# nrf9230_engb_cellrf register map
Vendor: Nordic Semiconductor; Series: nRF92; File version: 1
CPU: CM0 r0p0, little endian, no MPU, no FPU, 2 interrupt priority bits, 33 interrupts
Registers are 32-bit, read-write, reset 0x0 unless marked. A register's access mark holds for its fields unless they carry their own. Offsets are from the block's base; [hi:lo] are bit positions; {n}, {i} and the like mark numbered series; 'fields as' and 'values as' point back to an identical list.

## RXDFEGNSS — HALTI_RX_register_map AhmaRx Digital control register map
Base 0x46034000
0x00 TASKS_RX_START_DIG wo — Starts RX digital filtering.
  [0] TASKS_RX_START_DIG
    1=Trigger task
0x04 TASKS_RX_STOP_DIG wo — Stops RX digital filtering.
  [0] TASKS_RX_STOP_DIG
    1=Trigger task
0x08 TASKS_RX_START_DATA wo — Starts RX data transfer.
  [0] TASKS_RX_START_DATA
    1=Trigger task
0x0C TASKS_RX_STOP_DATA wo — Stops RX data transfer.
  [0] TASKS_RX_STOP_DATA
    1=Trigger task
0x10 TASKS_RX_START_NBPM wo — Starts narrow band power measurement.
  [0] TASKS_RX_START_NBPM
    1=Trigger task
0x18 TASKS_RX_CAPT_SAMPLE_CNT_0 wo — Captures sample counter value to RX_SAMPLE_CNT_CAPT_0 register.
  [0] TASKS_RX_CAPT_SAMPLE_CNT_0
    1=Trigger task
0x1C TASKS_RX_CAPT_SAMPLE_CNT_1 wo — Captures sample counter value to RX_SAMPLE_CNT_CAPT_1 register.
  [0] TASKS_RX_CAPT_SAMPLE_CNT_1
    1=Trigger task
0x20 TASKS_RX_LATCHREADREG wo — Latches set of read-only registers.
  [0] TASKS_RX_LATCHREADREG
    1=Trigger task
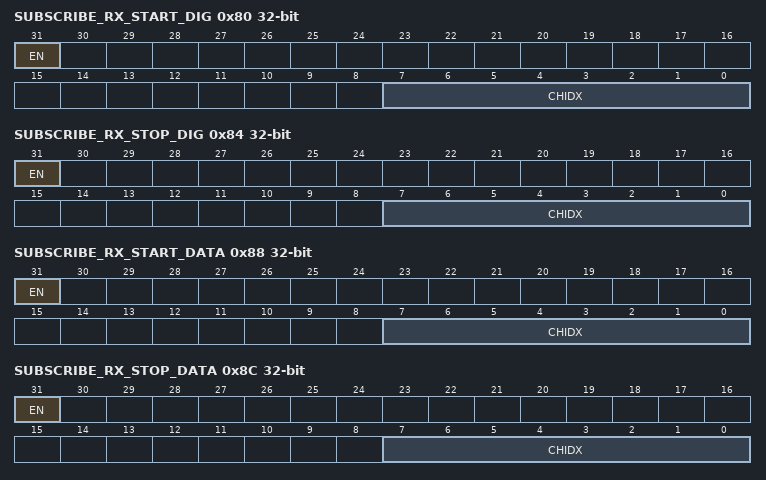
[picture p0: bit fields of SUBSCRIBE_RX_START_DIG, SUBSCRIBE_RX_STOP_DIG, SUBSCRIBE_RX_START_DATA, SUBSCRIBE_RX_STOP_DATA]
0x80 SUBSCRIBE_RX_START_DIG — Subscribe configuration for task RX_START_DIG
  [31] EN
    0=Disabled (Disable subscription); 1=Enabled (Enable subscription)
  [7:0] CHIDX — DPPI channel that task RX_START_DIG will subscribe to
0x84 SUBSCRIBE_RX_STOP_DIG — Subscribe configuration for task RX_STOP_DIG
  [31] EN
    values as SUBSCRIBE_RX_START_DIG.EN
  [7:0] CHIDX — DPPI channel that task RX_STOP_DIG will subscribe to
0x88 SUBSCRIBE_RX_START_DATA — Subscribe configuration for task RX_START_DATA
  [31] EN
    values as SUBSCRIBE_RX_START_DIG.EN
  [7:0] CHIDX — DPPI channel that task RX_START_DATA will subscribe to
0x8C SUBSCRIBE_RX_STOP_DATA — Subscribe configuration for task RX_STOP_DATA
  [31] EN
    values as SUBSCRIBE_RX_START_DIG.EN
  [7:0] CHIDX — DPPI channel that task RX_STOP_DATA will subscribe to
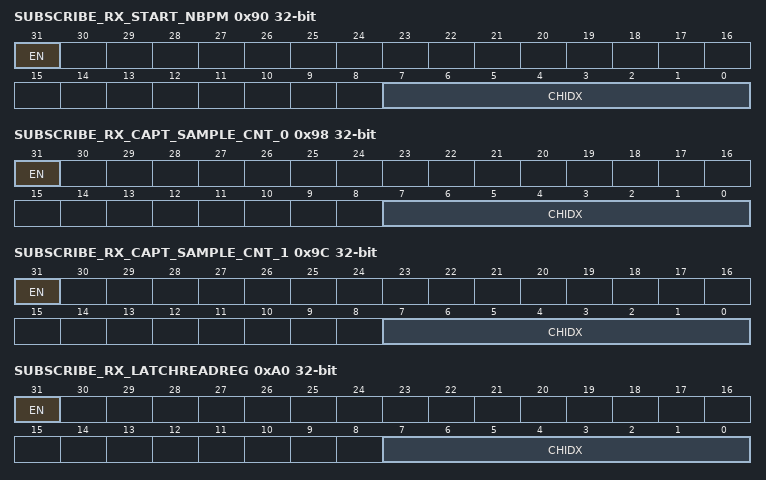
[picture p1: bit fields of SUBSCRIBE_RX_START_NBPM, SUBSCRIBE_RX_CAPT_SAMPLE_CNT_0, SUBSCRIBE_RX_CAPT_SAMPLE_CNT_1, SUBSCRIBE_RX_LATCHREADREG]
0x90 SUBSCRIBE_RX_START_NBPM — Subscribe configuration for task RX_START_NBPM
  [31] EN
    values as SUBSCRIBE_RX_START_DIG.EN
  [7:0] CHIDX — DPPI channel that task RX_START_NBPM will subscribe to
0x98 SUBSCRIBE_RX_CAPT_SAMPLE_CNT_0 — Subscribe configuration for task RX_CAPT_SAMPLE_CNT_0
  [31] EN
    values as SUBSCRIBE_RX_START_DIG.EN
  [7:0] CHIDX — DPPI channel that task RX_CAPT_SAMPLE_CNT_0 will subscribe to
0x9C SUBSCRIBE_RX_CAPT_SAMPLE_CNT_1 — Subscribe configuration for task RX_CAPT_SAMPLE_CNT_1
  [31] EN
    values as SUBSCRIBE_RX_START_DIG.EN
  [7:0] CHIDX — DPPI channel that task RX_CAPT_SAMPLE_CNT_1 will subscribe to
0xA0 SUBSCRIBE_RX_LATCHREADREG — Subscribe configuration for task RX_LATCHREADREG
  [31] EN
    values as SUBSCRIBE_RX_START_DIG.EN
  [7:0] CHIDX — DPPI channel that task RX_LATCHREADREG will subscribe to
0x100 EVENTS_RX_ADC_OVERFLOW — ADC overflow occurred.
  [0] EVENTS_RX_ADC_OVERFLOW
    0=NotGenerated (Event not generated); 1=Generated (Event generated)
0x104 EVENTS_RX_ADC_OVERFLOW_REM — ADC overflow removed.
  [0] EVENTS_RX_ADC_OVERFLOW_REM
    values as EVENTS_RX_ADC_OVERFLOW.EVENTS_RX_ADC_OVERFLOW
0x108 EVENTS_RX_NBPM_READY — Narrow band power measuremnt ready.
  [0] EVENTS_RX_NBPM_READY
    values as EVENTS_RX_ADC_OVERFLOW.EVENTS_RX_ADC_OVERFLOW
0x110 EVENTS_RX_SAMPLE_CNT_COMP_0 — RX sample count matches to value in RX_SAMPLE_CNT_COMP_0 register.
  [0] EVENTS_RX_SAMPLE_CNT_COMP_0
    values as EVENTS_RX_ADC_OVERFLOW.EVENTS_RX_ADC_OVERFLOW
0x114 EVENTS_RX_SAMPLE_CNT_COMP_1 — RX sample count matches to value in RX_SAMPLE_CNT_COMP_1 register.
  [0] EVENTS_RX_SAMPLE_CNT_COMP_1
    values as EVENTS_RX_ADC_OVERFLOW.EVENTS_RX_ADC_OVERFLOW
0x118 EVENTS_RX_SAMPLE_CNT_WRAP — RX sample counter wraps.
  [0] EVENTS_RX_SAMPLE_CNT_WRAP
    values as EVENTS_RX_ADC_OVERFLOW.EVENTS_RX_ADC_OVERFLOW
0x11C EVENTS_RX_DATA_OVERFLOW — RX data overflow occurred.
  [0] EVENTS_RX_DATA_OVERFLOW
    values as EVENTS_RX_ADC_OVERFLOW.EVENTS_RX_ADC_OVERFLOW
0x120 EVENTS_RX_SAMPLE_CNT_CAPT_0 — RX sample count value is captured to RX_SAMPLE_CNT_CAPT_0 register.
  [0] EVENTS_RX_SAMPLE_CNT_CAPT_0
    values as EVENTS_RX_ADC_OVERFLOW.EVENTS_RX_ADC_OVERFLOW
0x124 EVENTS_RX_SAMPLE_CNT_CAPT_1 — RX sample count value is captured to RX_SAMPLE_CNT_CAPT_1 register.
  [0] EVENTS_RX_SAMPLE_CNT_CAPT_1
    values as EVENTS_RX_ADC_OVERFLOW.EVENTS_RX_ADC_OVERFLOW
0x128 EVENTS_RX_READREGLATCHED — Set of read-only registers lacthed.
  [0] EVENTS_RX_READREGLATCHED
    values as EVENTS_RX_ADC_OVERFLOW.EVENTS_RX_ADC_OVERFLOW
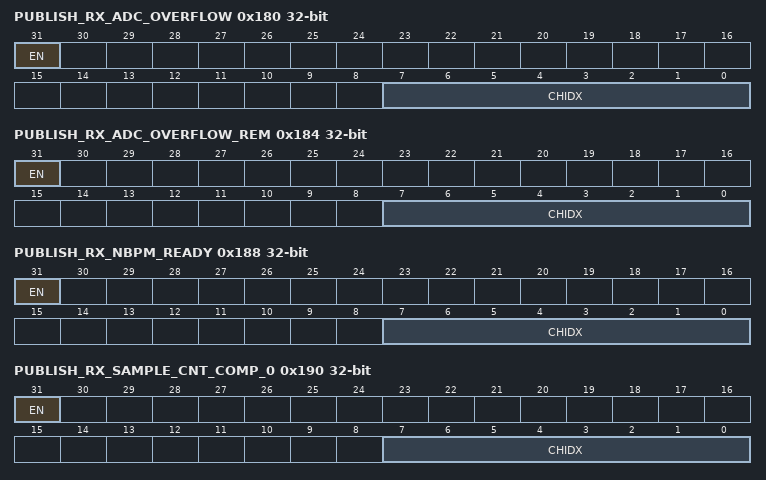
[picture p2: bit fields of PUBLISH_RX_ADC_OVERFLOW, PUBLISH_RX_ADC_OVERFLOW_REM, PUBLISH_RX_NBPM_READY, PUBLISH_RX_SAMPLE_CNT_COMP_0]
0x180 PUBLISH_RX_ADC_OVERFLOW — Publish configuration for event RX_ADC_OVERFLOW
  [31] EN
    0=Disabled (Disable publishing); 1=Enabled (Enable publishing)
  [7:0] CHIDX — DPPI channel that event RX_ADC_OVERFLOW will publish to
0x184 PUBLISH_RX_ADC_OVERFLOW_REM — Publish configuration for event RX_ADC_OVERFLOW_REM
  [31] EN
    values as PUBLISH_RX_ADC_OVERFLOW.EN
  [7:0] CHIDX — DPPI channel that event RX_ADC_OVERFLOW_REM will publish to
0x188 PUBLISH_RX_NBPM_READY — Publish configuration for event RX_NBPM_READY
  [31] EN
    values as PUBLISH_RX_ADC_OVERFLOW.EN
  [7:0] CHIDX — DPPI channel that event RX_NBPM_READY will publish to
0x190 PUBLISH_RX_SAMPLE_CNT_COMP_0 — Publish configuration for event RX_SAMPLE_CNT_COMP_0
  [31] EN
    values as PUBLISH_RX_ADC_OVERFLOW.EN
  [7:0] CHIDX — DPPI channel that event RX_SAMPLE_CNT_COMP_0 will publish to
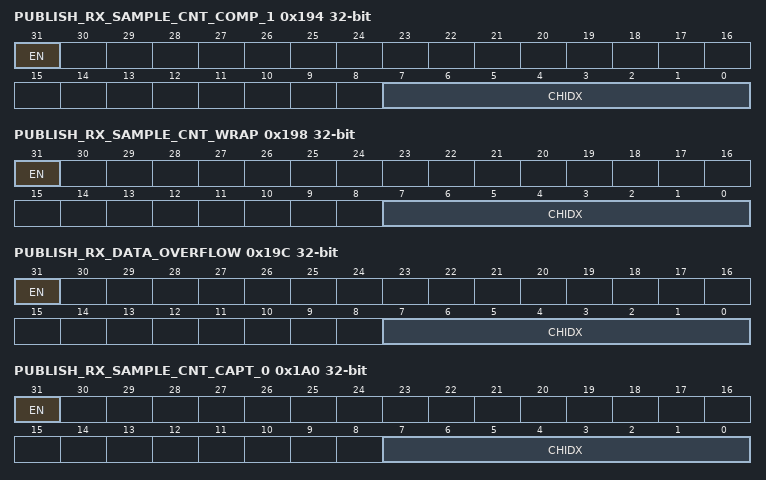
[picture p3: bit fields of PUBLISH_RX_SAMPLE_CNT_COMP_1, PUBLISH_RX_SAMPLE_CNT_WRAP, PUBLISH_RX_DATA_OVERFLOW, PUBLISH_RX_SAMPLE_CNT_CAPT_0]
0x194 PUBLISH_RX_SAMPLE_CNT_COMP_1 — Publish configuration for event RX_SAMPLE_CNT_COMP_1
  [31] EN
    values as PUBLISH_RX_ADC_OVERFLOW.EN
  [7:0] CHIDX — DPPI channel that event RX_SAMPLE_CNT_COMP_1 will publish to
0x198 PUBLISH_RX_SAMPLE_CNT_WRAP — Publish configuration for event RX_SAMPLE_CNT_WRAP
  [31] EN
    values as PUBLISH_RX_ADC_OVERFLOW.EN
  [7:0] CHIDX — DPPI channel that event RX_SAMPLE_CNT_WRAP will publish to
0x19C PUBLISH_RX_DATA_OVERFLOW — Publish configuration for event RX_DATA_OVERFLOW
  [31] EN
    values as PUBLISH_RX_ADC_OVERFLOW.EN
  [7:0] CHIDX — DPPI channel that event RX_DATA_OVERFLOW will publish to
0x1A0 PUBLISH_RX_SAMPLE_CNT_CAPT_0 — Publish configuration for event RX_SAMPLE_CNT_CAPT_0
  [31] EN
    values as PUBLISH_RX_ADC_OVERFLOW.EN
  [7:0] CHIDX — DPPI channel that event RX_SAMPLE_CNT_CAPT_0 will publish to
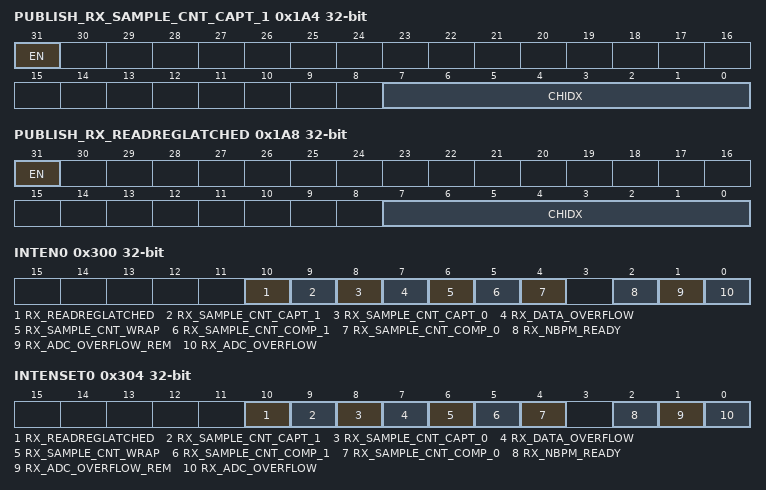
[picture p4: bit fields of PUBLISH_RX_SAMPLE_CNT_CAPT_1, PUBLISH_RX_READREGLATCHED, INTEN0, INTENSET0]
0x1A4 PUBLISH_RX_SAMPLE_CNT_CAPT_1 — Publish configuration for event RX_SAMPLE_CNT_CAPT_1
  [31] EN
    values as PUBLISH_RX_ADC_OVERFLOW.EN
  [7:0] CHIDX — DPPI channel that event RX_SAMPLE_CNT_CAPT_1 will publish to
0x1A8 PUBLISH_RX_READREGLATCHED — Publish configuration for event RX_READREGLATCHED
  [31] EN
    values as PUBLISH_RX_ADC_OVERFLOW.EN
  [7:0] CHIDX — DPPI channel that event RX_READREGLATCHED will publish to
0x300 INTEN0 — Enable or disable interrupt
  [all] fields
    0=Disabled; 1=Enabled
  [10] RX_READREGLATCHED — Enable or disable interrupt for event RX_READREGLATCHED
  [9] RX_SAMPLE_CNT_CAPT_1 — Enable or disable interrupt for event RX_SAMPLE_CNT_CAPT_1
  [8] RX_SAMPLE_CNT_CAPT_0 — Enable or disable interrupt for event RX_SAMPLE_CNT_CAPT_0
  [7] RX_DATA_OVERFLOW — Enable or disable interrupt for event RX_DATA_OVERFLOW
  [6] RX_SAMPLE_CNT_WRAP — Enable or disable interrupt for event RX_SAMPLE_CNT_WRAP
  [5] RX_SAMPLE_CNT_COMP_1 — Enable or disable interrupt for event RX_SAMPLE_CNT_COMP_1
  [4] RX_SAMPLE_CNT_COMP_0 — Enable or disable interrupt for event RX_SAMPLE_CNT_COMP_0
  [2] RX_NBPM_READY — Enable or disable interrupt for event RX_NBPM_READY
  [1] RX_ADC_OVERFLOW_REM — Enable or disable interrupt for event RX_ADC_OVERFLOW_REM
  [0] RX_ADC_OVERFLOW — Enable or disable interrupt for event RX_ADC_OVERFLOW
0x304 INTENSET0 — Enable interrupt
  [all] fields
    on read: 0=Disabled (Read: Disabled); 1=Enabled (Read: Enabled) | on write: 1=Set (Enable)
  [10] RX_READREGLATCHED — Write '1' to enable interrupt for event RX_READREGLATCHED
  [9] RX_SAMPLE_CNT_CAPT_1 — Write '1' to enable interrupt for event RX_SAMPLE_CNT_CAPT_1
  [8] RX_SAMPLE_CNT_CAPT_0 — Write '1' to enable interrupt for event RX_SAMPLE_CNT_CAPT_0
  [7] RX_DATA_OVERFLOW — Write '1' to enable interrupt for event RX_DATA_OVERFLOW
  [6] RX_SAMPLE_CNT_WRAP — Write '1' to enable interrupt for event RX_SAMPLE_CNT_WRAP
  [5] RX_SAMPLE_CNT_COMP_1 — Write '1' to enable interrupt for event RX_SAMPLE_CNT_COMP_1
  [4] RX_SAMPLE_CNT_COMP_0 — Write '1' to enable interrupt for event RX_SAMPLE_CNT_COMP_0
  [2] RX_NBPM_READY — Write '1' to enable interrupt for event RX_NBPM_READY
  [1] RX_ADC_OVERFLOW_REM — Write '1' to enable interrupt for event RX_ADC_OVERFLOW_REM
  [0] RX_ADC_OVERFLOW — Write '1' to enable interrupt for event RX_ADC_OVERFLOW
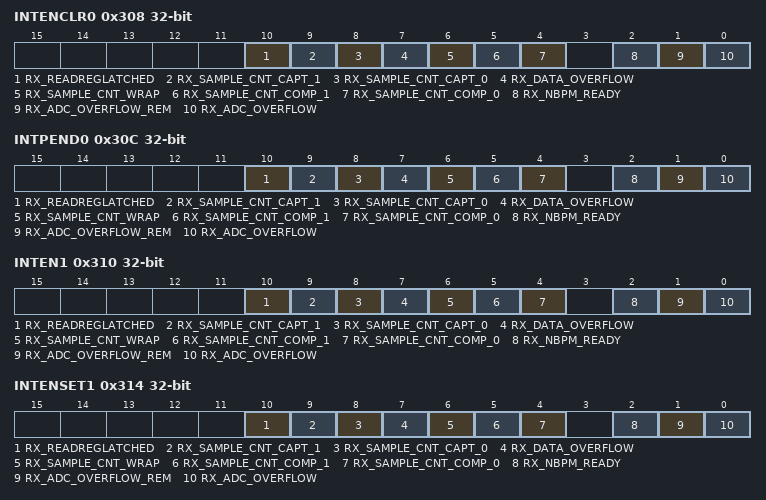
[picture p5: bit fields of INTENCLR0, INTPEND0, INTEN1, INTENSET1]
0x308 INTENCLR0 — Disable interrupt
  [all] fields
    on read: 0=Disabled (Read: Disabled); 1=Enabled (Read: Enabled) | on write: 1=Clear (Disable)
  [10] RX_READREGLATCHED — Write '1' to disable interrupt for event RX_READREGLATCHED
  [9] RX_SAMPLE_CNT_CAPT_1 — Write '1' to disable interrupt for event RX_SAMPLE_CNT_CAPT_1
  [8] RX_SAMPLE_CNT_CAPT_0 — Write '1' to disable interrupt for event RX_SAMPLE_CNT_CAPT_0
  [7] RX_DATA_OVERFLOW — Write '1' to disable interrupt for event RX_DATA_OVERFLOW
  [6] RX_SAMPLE_CNT_WRAP — Write '1' to disable interrupt for event RX_SAMPLE_CNT_WRAP
  [5] RX_SAMPLE_CNT_COMP_1 — Write '1' to disable interrupt for event RX_SAMPLE_CNT_COMP_1
  [4] RX_SAMPLE_CNT_COMP_0 — Write '1' to disable interrupt for event RX_SAMPLE_CNT_COMP_0
  [2] RX_NBPM_READY — Write '1' to disable interrupt for event RX_NBPM_READY
  [1] RX_ADC_OVERFLOW_REM — Write '1' to disable interrupt for event RX_ADC_OVERFLOW_REM
  [0] RX_ADC_OVERFLOW — Write '1' to disable interrupt for event RX_ADC_OVERFLOW
0x30C INTPEND0 ro — Pending interrupts
  [all] fields
    on read: 0=NotPending (Read: Not pending); 1=Pending (Read: Pending)
  [10] RX_READREGLATCHED — Read pending status of interrupt for event RX_READREGLATCHED
  [9] RX_SAMPLE_CNT_CAPT_1 — Read pending status of interrupt for event RX_SAMPLE_CNT_CAPT_1
  [8] RX_SAMPLE_CNT_CAPT_0 — Read pending status of interrupt for event RX_SAMPLE_CNT_CAPT_0
  [7] RX_DATA_OVERFLOW — Read pending status of interrupt for event RX_DATA_OVERFLOW
  [6] RX_SAMPLE_CNT_WRAP — Read pending status of interrupt for event RX_SAMPLE_CNT_WRAP
  [5] RX_SAMPLE_CNT_COMP_1 — Read pending status of interrupt for event RX_SAMPLE_CNT_COMP_1
  [4] RX_SAMPLE_CNT_COMP_0 — Read pending status of interrupt for event RX_SAMPLE_CNT_COMP_0
  [2] RX_NBPM_READY — Read pending status of interrupt for event RX_NBPM_READY
  [1] RX_ADC_OVERFLOW_REM — Read pending status of interrupt for event RX_ADC_OVERFLOW_REM
  [0] RX_ADC_OVERFLOW — Read pending status of interrupt for event RX_ADC_OVERFLOW
0x310 INTEN1 — Enable or disable interrupt
  fields as INTEN0
0x314 INTENSET1 — Enable interrupt
  fields as INTENSET0
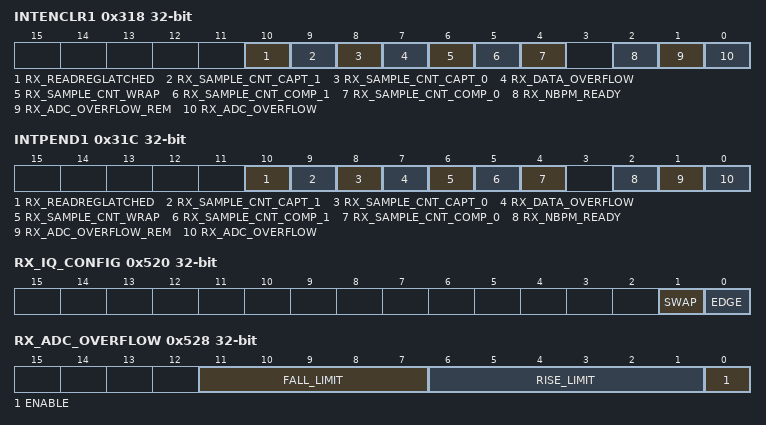
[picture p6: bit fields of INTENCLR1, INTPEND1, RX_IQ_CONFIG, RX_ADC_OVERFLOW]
0x318 INTENCLR1 — Disable interrupt
  fields as INTENCLR0
0x31C INTPEND1 ro — Pending interrupts
  fields as INTPEND0
0x400 RX_STATUS ro
  [0] NBPM_ACTIVE — Narrow band power meter status.
    0=Inactive (NBPM inactive); 1=Active (NBPM active)
0x500 RX_DIG_ENABLE — RX digital enable
  [0] ENABLE — Enable RX digital.
    0=Disabled; 1=Enabled
0x504 RX_DATA_ENABLE
  [0] ENABLE — This bit controls the sync reset signal of the RX data interface.
    0=Disabled; 1=Enabled
0x510 RX_CLK_ENABLE reset 0x1 — RX data enable
  [0] ENABLE — This bit enables the RX data interface clock.
    0=Disabled; 1=Enabled
0x51C RX_CONFIGDONE — RX configuration done.
  [0] ENABLE — This bit indicates that RX digital has been configured. This bit must be asserted at the end of the configuration so that e.g. synchronization of registers to the core works correctly. This bit must be deasserted when RX digital is disabled.
    0=ConfNotDone (Configuration not done); 1=ConfDone (Configuration done)
0x520 RX_IQ_CONFIG — I/Q config
  [1] SWAP — Swaps I and Q paths with each other.
    0=NoSwap; 1=Swapped
  [0] EDGE — Defines on which edge of ADC clock to sample I and Q data.
    0=Falling edge; 1=Rising edge
0x524 RX_ADC_CK_REQ — RX ADC clock request
  [0] REQ — Requests ADC clock.
    0=NoRequest; 1=Request
0x528 RX_ADC_OVERFLOW — RX ADC overflow detection
  [11:7] FALL_LIMIT — Specifies how many ADC clock cycles are elapsed before overflow is removed.
    0=1cycle; 1=2cycles; 31=32cycles
  [6:1] RISE_LIMIT — Specifies how many consecutive cycles with +2 or -2 value must be detected on ADC data input before overflow is detected.
    0=1cycle; 1=2cycles; 63=64cycles
  [0] ENABLE — Enable ADC overflow detection logic.
    0=Disabled; 1=Enabled
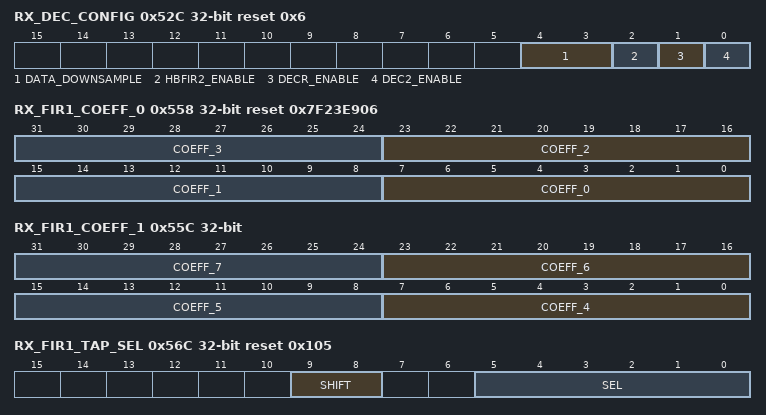
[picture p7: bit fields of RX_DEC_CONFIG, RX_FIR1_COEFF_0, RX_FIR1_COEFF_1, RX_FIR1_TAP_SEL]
0x52C RX_DEC_CONFIG reset 0x6 — RX decimation config
  [4:3] DATA_DOWNSAMPLE — Downsample selection of RX data output.
    0=Disabled; 1=DownsampleBy2; 2=DownsampleBy4; 3=DownsampleBy8
  [2] HBFIR2_ENABLE — Enable half-band FIR with decimation by 2.
    0=Disabled (Disable (i.e. bypass)); 1=Enabled
  [1] DECR_ENABLE — Enable CIC filter with decimation by factor R. R is 5 when normal decimation mode is selected and 4 when alternative decimation mode is selected.
    0=Disabled (Disable (i.e. bypass)); 1=Enabled
  [0] DEC2_ENABLE — Enable CIC filter with decimation by 2.
    0=Disabled (Disable (i.e. bypass)); 1=Enabled
0x530 RX_ALT_DEC_MODE — Alternative decimation mode.
  [0] MODE — Alternative decimation mode selection.
    0=Normal mode; 1=Alternative mode
0x534 RX_DCCOMP_HOLD — DC offset compensation hold
  [0] HOLD — With this bit, the DC estimation LPF can be put into hold mode.
    0=Running; 1=Hold
0x538 RX_DCCOMP_SEL — DC offset compensation selection
  [1:0] SEL — Selection of DC value removal.
    0=Internal (estimated) DC value subtracted from output; 1=External (register) DC value subtracted from output; 2=Bypassed (DC compensation is bypassed.)
0x53C RX_DCCOMP_COEFF_N — Coefficient N value of DC estimation LPF.
  [3:0] COEFF_N — Coefficient N value of DC estimation LPF. This value can be updated while RX digital is active.
0x540 RX_DCCOMP_INIT_I — Initialization value of DC I estimation LPF.
  [16:0] INIT — Initialization value (signed) of DC I estimation LPF. Taken into use when RX digital is activated. This value can be updated while RX digital is active.
0x544 RX_DCCOMP_INIT_Q — Initialization value of DC Q estimation LPF.
  [16:0] INIT — Initialization value (signed) of DC Q estimation LPF. Taken into use when RX digital is activated. This value can be updated while RX digital is active.
0x548 RX_DCCOMP_EXT_I — External value of DC I offset compensation.
  [16:0] EXT — External value (signed) of DC I offset compensation. This value is used when external DC estimation is selected by RX_DCCOMP_SEL register and can be updated while RX digital is active.
0x54C RX_DCCOMP_EXT_Q — External value of DC Q offset compensation.
  [16:0] EXT — External value (signed) of DC Q offset compensation. This value is used when external DC estimation is selected by RX_DCCOMP_SEL register and can be updated while RX digital is active.
0x550 RX_DCCOMP_EST_I ro — Estimated DC I value from DC estimation LPF.
  [16:0] EST — Estimated DC I value (signed) from DC estimation LPF.
0x554 RX_DCCOMP_EST_Q ro — Estimated DC Q value from DC estimation LPF.
  [16:0] EST — Estimated DC Q value (signed) from DC estimation LPF.
0x558 RX_FIR1_COEFF_0 reset 0x7F23E906 — FIR 1 coefficients 0, 1, 2 and 3.
  [8n+7:8n] COEFF_{n} (n=0..3) — FIR 1 coefficient {n} (signed value).
0x55C RX_FIR1_COEFF_1 — FIR 1 coefficients 4, 5, 6 and 7.
  [8n-25:8n-32] COEFF_{n} (n=4..7) — FIR 1 coefficient {n} (signed value).
0x56C RX_FIR1_TAP_SEL reset 0x105 — Number of taps used in FIR 1.
  [9:8] SHIFT — Shift-right the output bits of FIR 1 filter.
    {v}=ShiftBy{v+5} (Shift-right by {v+5}) (v=0..3)
  [5:0] SEL — Number of taps used in FIR 1. The maximum number of taps is 40.
    0=2taps; 1=3taps; 5=7taps; 15=17taps; 25=27taps; 37=39taps
0x588 RX_SCALER_FINE_GAIN — Scaler fine gain.
  [7:0] GAIN — Controls RX digital output fine gain, in ca. 0.034 dB steps. Total gain is sum of SCALER_FINE_GAIN and SCALER_COARSE_GAIN. This value can be updated while RX digital is active.
    0=0p000dB (+0.000 dB); 1=0p034dB (+0.034 dB); 2=0p068dB (+0.068 dB); 255=6p004dB (+6.004 dB)
0x58C RX_SCALER_COARSE_GAIN — Scaler coarse gain.
  [4:0] GAIN — Controls RX digital output coarse gain, in 6.02 dB steps. Total gain is sum of SCALER_FINE_GAIN and SCALER_COARSE_GAIN. This value can be updated while RX digital is active.
    0=m90p31dB (-90.31 dB); 1=m84p29dB (-84.29 dB); 14=m6p02dB (-6.02 dB); 15=0p00dB (+0.00 dB); 16=6p02dB (+6.02 dB); 30=90p31dB (+90.31 dB); 31=96p33dB (+96.33 dB)
0x590 RX_NBPM_DATA_SEL reset 0x1 — Narrow band power meter input data selection.
  [0] SEL — Selects input data of narrow band power meter.
    0=DecAndFilt (Decimation and filtering block output.); 1=Scaler output
0x594 RX_NBPM_FACTOR_L — Narrow band power meter input data selection.
  [2:0] FACTOR — Specifies how many bits of input data are downshifted before data is feed into narrow band power meter.
    0=0bit; 1=1bit; 7=7bits
0x598 RX_NBPM_FACTOR_M — Narrow band power meter factor M.
  [5:0] FACTOR — Number of consecutive power measurements on which max power is performed.
    0=1 measurement; 1=2 measurements; 63=64 measurements
0x59C RX_NBPM_FACTOR_K — Narrow band power meter factor K.
  [11:0] FACTOR — Number of samples considered in power and DC measurement (i.e. accumulation).
    0=1sample; 1=2samples; 0xFFF=4096samples
0x5A0 RX_NBPM_FACTOR_N — Narrow band power meter factor N.
  [3:0] FACTOR — Specifies how many bits are downshifted after power and DC accumulation.
    0=0bit; 1=1bit; 15=15bits
0x5A4 RX_NBPM_POWER ro — Measured narrow band power.
  [31:0] POWER — This is a squared value. This registers can be read after RX_NBPM_READY event is occurred.
0x5A8 RX_NBPM_DC_I ro — Measured narrow band DC I.
  [15:0] DC — This is a signed value. This registers can be read after RX_NBPM_READY event is occurred.
0x5AC RX_NBPM_DC_Q ro — Measured narrow band DC Q.
  fields as RX_NBPM_DC_I
0x5D0 RX_SAMPLE_CNT_COMP_0 — RX sample count compare 0.
  [31:0] COMP — When this value matches internal RX sample counter, the RX_SAMPLE_CNT_COMP_0 event is generated.
0x5D4 RX_SAMPLE_CNT_CAPT_0 ro — RX sample count capture 0.
  [31:0] CAPT — The task RX_CAPT_SAMPLE_CNT_0 captures the sample counter value into this register. This registers can be read after RX_SAMPLE_CNT_CAPT_0 event is occurred.
0x5D8 RX_SAMPLE_CNT_COMP_1 — RX sample count compare 1.
  [31:0] COMP — When this value matches internal RX sample counter, the RX_SAMPLE_CNT_COMP_1 event is generated.
0x5DC RX_SAMPLE_CNT_CAPT_1 ro — RX sample count capture 1.
  [31:0] CAPT — The task RX_CAPT_SAMPLE_CNT_1 captures the sample counter value into this register. This registers can be read after RX_SAMPLE_CNT_CAPT_1 event is occurred.
0x600 RX_DIG_SPARE — Spare register for digital.
  [15:0] SPARE — Spare bits.
0x604 RX_ABB_CAL_STORE — Stored value of RX ABB RC calibration result.
  [4:0] RESULT — SW stores RC calibration value into this register.
0x608 RX_DEBUG_CORE — RX digital core debug register.
  [2:0] BYPASS — RX digital core bypass.
    0=Normal operation; 1=HB FIR 1 outputs connected to RX data outputs; 2=Int3Dec4 outputs connected to RX data outputs; 3=DecR outputs connected to RX data outputs; 4=Dec2 outputs connected to RX data outputs
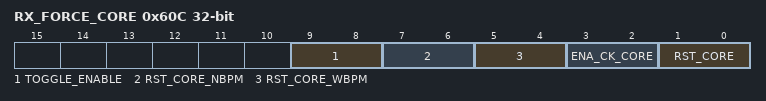
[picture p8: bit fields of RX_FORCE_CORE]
0x60C RX_FORCE_CORE — RX digital core force register.
  [all] fields
    0=Normal operation; 1=NA (Not available); 2=Low (Forced to low); 3=High (Forced to high)
  [9:8] TOGGLE_ENABLE — Force toggleDelayEnable.
  [7:6] RST_CORE_NBPM — Force rstCoreNbpm.
  [5:4] RST_CORE_WBPM — Force rstCoreWbpm.
  [3:2] ENA_CK_CORE — Force enaCkCore.
  [1:0] RST_CORE — Force rstCore.
{0x610+4i} RX_DEBUG_{i}_PSEL (i=0..7) — RX debug {i} port/pin selection.
  [3:0] SELECT — Connection selection.
0x630 RX_FORCE_CK_REQ — RX debug 7 port/pin selection.
  [0] FORCE — This bit is used to force the ADC clock ON in the emulator environment. This bit is combined with RX_ADC_CK_REQ by the OR-gate.
    0=NoEffect; 1=Forced (ADC clock forced ON)
